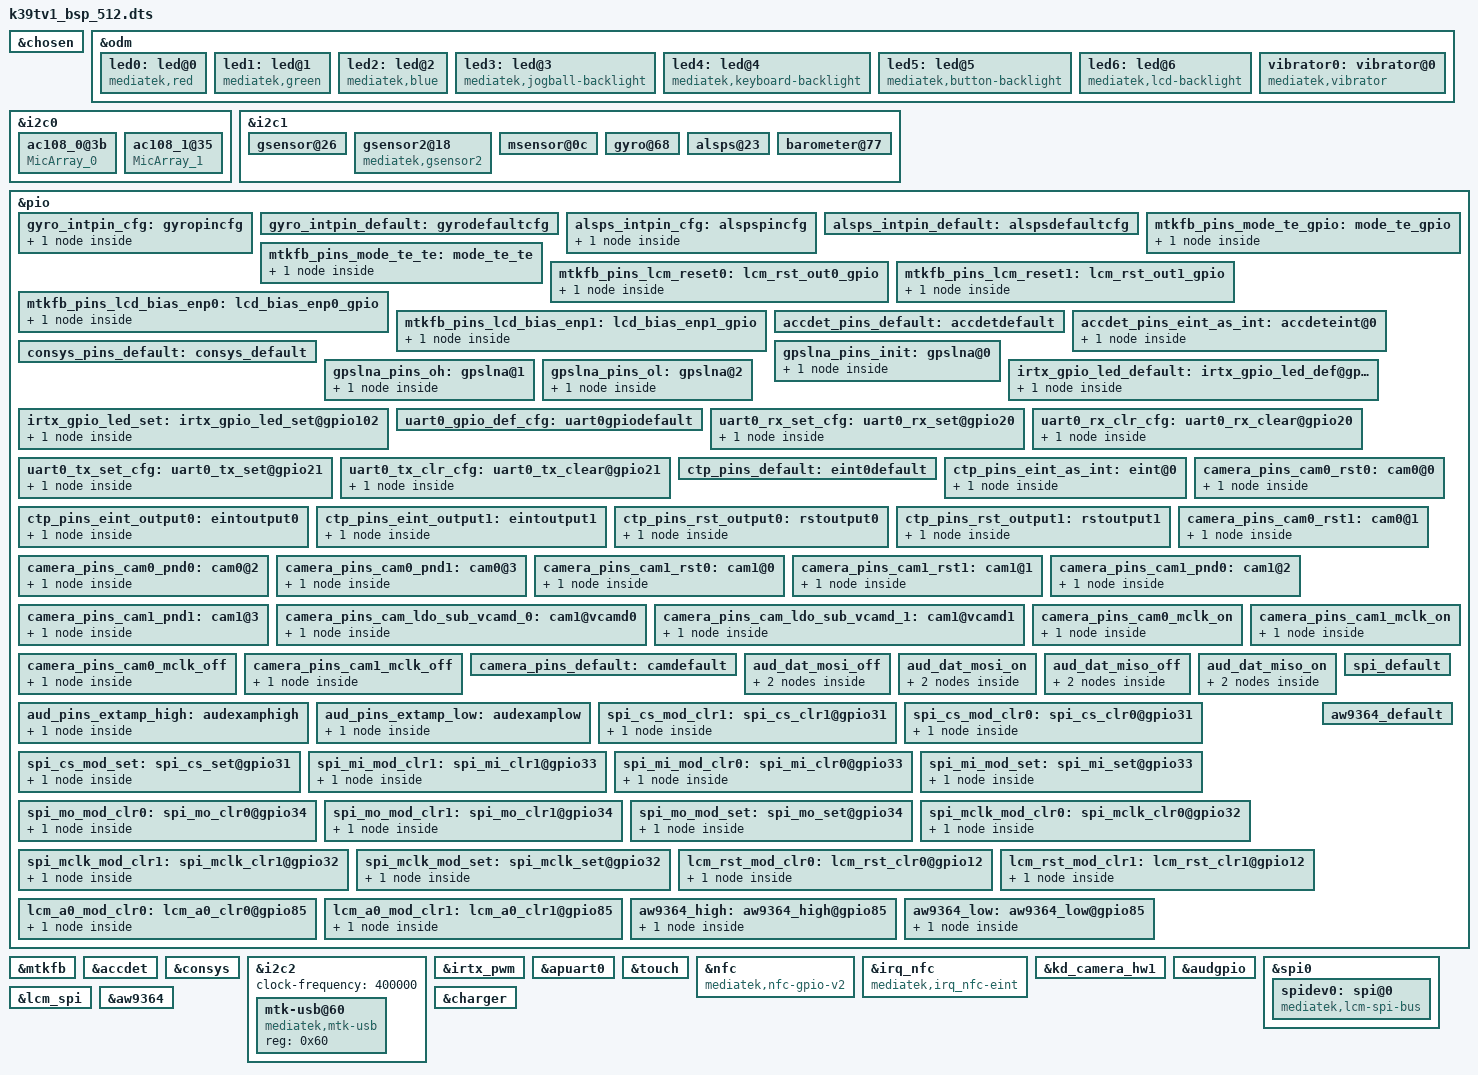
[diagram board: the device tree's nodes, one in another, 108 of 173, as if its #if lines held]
#include <generated/autoconf.h>
/dts-v1/;

#ifdef CONFIG_MTK_DTBO_FEATURE
/plugin/;
#include <dt-bindings/mmc/mt6739-msdc.h>
#include <dt-bindings/pinctrl/mt6739-pinfunc.h>
#else
#include "mt6739.dts"
#endif

/* chosen */
&chosen {
	bootargs = "console=tty0 console=ttyMT0,921600n1 root=/dev/ram initrd=0x44000000,\
0x1000000 loglevel=8 androidboot.selinux=permissive androidboot.hardware=mt6739 initcall_debug=1";
	/* fpga may has no lk, we need to specify display info here */
	/* fb buffer is reserved using this dts by memory node above */

	atag,videolfb-fb_base_l = <0x5e605000>;
	atag,videolfb-fb_base_h = <0>;
	atag,videolfb-islcmfound = <1>;
	atag,videolfb-islcm_inited = <0>;
	atag,videolfb-fps= <6000>;
	atag,videolfb-vramSize= <0x017bb000>;
	atag,videolfb-lcmname= "nt35521_hd_dsi_vdo_truly_nt50358_drv";
};

&odm {
	led0:led@0 {
		compatible = "mediatek,red";
		led_mode = <1>;
		data = <0>;
		pwm_config = <0 0 0 0 0>;
	};
	led1:led@1 {
		compatible = "mediatek,green";
		led_mode = <1>;
		data = <1>;
		pwm_config = <0 0 0 0 0>;
	};
	led2:led@2 {
		compatible = "mediatek,blue";
		led_mode = <1>;
		data = <2>;
		pwm_config = <0 0 0 0 0>;
	};
	led3:led@3 {
		compatible = "mediatek,jogball-backlight";
		led_mode = <0>;
		data = <1>;
		pwm_config = <0 0 0 0 0>;
	};
	led4:led@4 {
		compatible = "mediatek,keyboard-backlight";
		led_mode = <0>;
		data = <1>;
		pwm_config = <0 0 0 0 0>;
	};
	led5:led@5 {
		compatible = "mediatek,button-backlight";
		led_mode = <3>;
		data = <2>;
		pwm_config = <0 0 0 0 0>;
	};
	led6:led@6 {
		compatible = "mediatek,lcd-backlight";
		led_mode = <5>;
		data = <1>;
		pwm_config = <0 2 0 0 0>;
	};
	vibrator0:vibrator@0 {
		compatible = "mediatek,vibrator";
		vib_timer = <25>;
		vib_limit = <9>;
		vib_vol= <9>;
	};
};

/*ac108*/
&i2c0 {
	ac108_0@3b {
		compatible = "MicArray_0";  
		reg = <0x3b>;
		voltage_enable ="vmch";
	};
	ac108_1@35 {
		compatible = "MicArray_1";  
		reg = <0x35>;
		voltage_enable ="vmch";
	};	
};
	
&i2c1 {
/*  start sensor */
	gsensor@26 {
		i2c_num	= <1>;
		direction = <5>;
		power_id = <0xffff>;
		power_vol = <0>;
		firlen = <16>;
		is_batch_supported = <1>;
	};

	gsensor2@18 {
		compatible = "mediatek,gsensor2";  
		reg = <0x18>;
		
		i2c_num	= <1>;
		direction = <5>;
		power_id = <0xffff>;
		power_vol = <0>;
		firlen = <16>;
		is_batch_supported = <1>;
	};
	
	msensor@0c {
		i2c_num = <1>;
		i2c_addr = <0x0d 0 0 0>;
		direction = <8>;
		power_id = <0xffff>;
		power_vol = <0>;
		is_batch_supported = <0>;
	};

	gyro@68 {
		pinctrl-names = "pin_default", "pin_cfg";
		pinctrl-0 = <&gyro_intpin_default>;
		pinctrl-1 = <&gyro_intpin_cfg>;
		i2c_num = <1>;
		i2c_addr = <0x68 0 0 0>;
		direction = <5>;
		power_id = <0xffff>;
		power_vol = <0>;
		firlen = <0>;
		is_batch_supported = <0>;
	};

	alsps@23 {
		pinctrl-names = "pin_default", "pin_cfg";
		pinctrl-0 = <&alsps_intpin_default>;
		pinctrl-1 = <&alsps_intpin_cfg>;
		status = "okay";
		/* customization */
		i2c_num = <1>;
		i2c_addr = <0x23 0 0 0>;
		polling_mode_ps = <0>;
		polling_mode_als = <1>;
		power_id = <0xffff>;
		power_vol = <0>;
		als_level = <0 328 861 1377 3125 7721 7767 12621 23062 28430 33274 47116 57694 57694 65535>;
		als_value = <0 133 304 502 1004 2005 3058 5005 8008 10010 12000 16000 20000 20000 20000 20000>;
		ps_threshold_high = <26>;
		ps_threshold_low = <21>;
		is_batch_supported_ps = <0>;
		is_batch_supported_als = <0>;
	};

	barometer@77 {
		i2c_num = <1>;
		i2c_addr = <0x77 0 0 0>;
		direction = <0>;
		power_id = <0xffff>;
		power_vol = <0>;
		firlen = <32>;
		is_batch_supported = <0>;
	};
/* end sensor */
};

/* sensor gpio standization */
&pio {

	gyro_intpin_cfg: gyropincfg {

	    pins_cmd_dat {
			pins = <PINMUX_GPIO5__FUNC_GPIO5>;
			slew-rate = <0>;
			bias-pull-down = <00>;
		};
	};

	gyro_intpin_default: gyrodefaultcfg {

	};
};

&pio {
	alsps_intpin_cfg: alspspincfg {

		pins_cmd_dat {
			pins = <PINMUX_GPIO102__FUNC_GPIO102>;
			slew-rate = <0>;
			bias-pull-up = <MTK_PUPD_SET_R1R0_01>;
		};
	};

	alsps_intpin_default: alspsdefaultcfg {

	};
};

/* sensor end */

/* DISPSYS GPIO standardization */
&pio {
	mtkfb_pins_mode_te_gpio: mode_te_gpio {
		pins_cmd_dat {
			pins = <PINMUX_GPIO84__FUNC_DSI_TE>;
		};
	};

	mtkfb_pins_mode_te_te: mode_te_te {
		pins_cmd_dat {
			pins = <PINMUX_GPIO84__FUNC_DSI_TE>;
		};
	};

	mtkfb_pins_lcm_reset0: lcm_rst_out0_gpio {
		pins_cmd_dat {
			pins = <PINMUX_GPIO83__FUNC_LCM_RST>;
			slew-rate = <1>;
			output-low;
		};
	};

	mtkfb_pins_lcm_reset1: lcm_rst_out1_gpio {
		pins_cmd_dat {
			pins = <PINMUX_GPIO83__FUNC_LCM_RST>;
			slew-rate = <1>;
			output-high;
		};
	};

	mtkfb_pins_lcd_bias_enp0: lcd_bias_enp0_gpio {
		pins_cmd_dat {
			pins = <PINMUX_GPIO102__FUNC_GPIO102>;
			slew-rate = <1>;
			output-low;
		};
	};
	mtkfb_pins_lcd_bias_enp1: lcd_bias_enp1_gpio {
		pins_cmd_dat {
			pins = <PINMUX_GPIO102__FUNC_GPIO102>;
			slew-rate = <1>;
			output-high;
		};
	};

};

&mtkfb {
	pinctrl-names = "mode_te_gpio", "mode_te_te", "lcm_rst_out0_gpio",
		"lcm_rst_out1_gpio", "lcd_bias_enp0_gpio", "lcd_bias_enp1_gpio";
	pinctrl-0 = <&mtkfb_pins_mode_te_gpio>;
	pinctrl-1 = <&mtkfb_pins_mode_te_te>;
	pinctrl-2 = <&mtkfb_pins_lcm_reset0>;
	pinctrl-3 = <&mtkfb_pins_lcm_reset1>;
	pinctrl-4 = <&mtkfb_pins_lcd_bias_enp0>;
	pinctrl-5 = <&mtkfb_pins_lcd_bias_enp1>;
	status = "okay";
};
/* DISPSYS GPIO standardization end */


/* accdet start */
&accdet {
	/* accdet micbias voltage: 0x07,2.7v;0x05,2.5v;0x02,1.9v */
	accdet-mic-vol = <6>;
	headset-mode-setting = <0x500 0x500 1 0x1f0 0x800 0x800 0x20 0x44>;
	accdet-plugout-debounce = <1>;
	/*1:ACC mode, 2:low cost without in bias, 6:low cost with in bias*/
	accdet-mic-mode = <2>;
	/* eint_level_trigger: 8,LEVEL_LOW(default);4,LEVEL_HIGH;others,LEVEL_LOW */
	headset-eint-level-pol = <8>;
	/*0--MD_MAX--UP_MAX--DW_MAX*/
	headset-three-key-threshold = <0 80 220 400>;
	headset-three-key-threshold-CDD = <0 121 192 600>;
	/*0--MD_MAX--VOICE_MAX--UP_MAX--DW_MAX*/
	headset-four-key-threshold = <0 58 121 192 400>;
	/* ACCDET GPIO standardization ACC mode no use */
	pinctrl-names = "default", "state_eint_as_int";
	pinctrl-0 = <&accdet_pins_default>;
	pinctrl-1 = <&accdet_pins_eint_as_int>;
	status = "okay";
};
&pio {
	accdet_pins_default: accdetdefault {
	};
	accdet_pins_eint_as_int: accdeteint@0 {
		pins_cmd_dat {
			pins = <PINMUX_GPIO13__FUNC_GPIO13>;
			slew-rate = <0>;
			bias-disable;
		};
	};
};
/* accdet end */
/* CONSYS GPIO standardization */
&pio {
	consys_pins_default: consys_default {
	};
	gpslna_pins_init: gpslna@0 {
		pins_cmd_dat {
			pins = <PINMUX_GPIO91__FUNC_GPIO91>;
			slew-rate = <0>;
			bias-disable;
			output-low;
		};
	};
	gpslna_pins_oh: gpslna@1 {
		pins_cmd_dat {
			pins = <PINMUX_GPIO91__FUNC_GPIO91>;
			slew-rate = <1>;
			output-high;
		};
	};
	gpslna_pins_ol: gpslna@2 {
		pins_cmd_dat {
			pins = <PINMUX_GPIO91__FUNC_GPIO91>;
			slew-rate = <1>;
			output-low;
		};
	};
};
&consys {
	pinctrl-names = "default", "gps_lna_state_init", "gps_lna_state_oh", "gps_lna_state_ol";
	pinctrl-0 = <&consys_pins_default>;
	pinctrl-1 = <&gpslna_pins_init>;
	pinctrl-2 = <&gpslna_pins_oh>;
	pinctrl-3 = <&gpslna_pins_ol>;
	status = "okay";
};
&i2c2 {
	#address-cells = <1>;
	#size-cells = <0>;
	clock-frequency = <400000>;

	mtk-usb@60 {
		compatible = "mediatek,mtk-usb";
		reg = <0x60>;
		status = "okay";
	};
};

/* IRTX GPIO Start */
&irtx_pwm {
	pinctrl-names = "irtx_gpio_led_default", "irtx_gpio_led_set";
	pinctrl-0 = <&irtx_gpio_led_default>;
	pinctrl-1 = <&irtx_gpio_led_set>;
	status = "okay";
};
&pio {
	/* IRTX GPIO Settings -Start */
	/* default: GPIO0, output, high */
	irtx_gpio_led_default:irtx_gpio_led_def@gpio102 {
		pins_cmd_dat {
			pins = <PINMUX_GPIO102__FUNC_GPIO102>;
			slew-rate = <1>;
			bias-disable;
			output-low;
			input-schmitt-enable = <0>;
		};
	};

	irtx_gpio_led_set:irtx_gpio_led_set@gpio102 {
		pins_cmd_dat {
			pins = <PINMUX_GPIO102__FUNC_GPIO102>;
			slew-rate = <1>;
			output-high;
		};
	};
}; /* IRTX GPIO Settings -End */

/* UART GPIO */
&apuart0 {
	pinctrl-names = "uart0_gpio_default",
			"uart0_rx_set",
			"uart0_rx_clear",
			"uart0_tx_set",
			"uart0_tx_clear";
	pinctrl-0 = <&uart0_gpio_def_cfg>;
	pinctrl-1 = <&uart0_rx_set_cfg>;
	pinctrl-2 = <&uart0_rx_clr_cfg>;
	pinctrl-3 = <&uart0_tx_set_cfg>;
	pinctrl-4 = <&uart0_tx_clr_cfg>;
	status = "okay";
};

&pio {
	/* UART GPIO Settings - Start */
	/* UART0: rx set, rx clear, tx clear, tx clear*/
	uart0_gpio_def_cfg:uart0gpiodefault {

	};
	uart0_rx_set_cfg:uart0_rx_set@gpio20 {
		pins_cmd_dat {
			pins = <PINMUX_GPIO20__FUNC_UART0RX>;
		};
	};
	uart0_rx_clr_cfg:uart0_rx_clear@gpio20 {
		pins_cmd_dat {
			pins = <PINMUX_GPIO20__FUNC_GPIO20>;
			slew-rate = <1>;
			output-high;
		};
	};
	uart0_tx_set_cfg:uart0_tx_set@gpio21 {
		pins_cmd_dat {
			pins = <PINMUX_GPIO21__FUNC_UART0TX>;
		};
	};
	uart0_tx_clr_cfg:uart0_tx_clear@gpio21 {
		pins_cmd_dat {
			pins = <PINMUX_GPIO21__FUNC_GPIO21>;
			slew-rate = <1>;
			output-high;
		};
	};
};/* UART GPIO end */

/* TOUCH start */
&touch {
	tpd-resolution = <480 854>;
	use-tpd-button = <0>;
	tpd-key-num = <3>;
	tpd-key-local= <139 172 158 0>;
	tpd-key-dim-local = <90 883 100 40 230 883 100 40 370 883 100 40 0 0 0 0>;
	tpd-max-touch-num = <5>;
	tpd-filter-enable = <1>;
	tpd-filter-pixel-density = <71>;
	tpd-filter-custom-prameters = <0 0 0 0 0 0 0 0 0 0 0 0>;
	tpd-filter-custom-speed = <0 0 0>;
	pinctrl-names = "default", "state_eint_as_int", "state_eint_output0", "state_eint_output1",
		"state_rst_output0", "state_rst_output1";
	pinctrl-0 = <&ctp_pins_default>;
	pinctrl-1 = <&ctp_pins_eint_as_int>;
	pinctrl-2 = <&ctp_pins_eint_output0>;
	pinctrl-3 = <&ctp_pins_eint_output1>;
	pinctrl-4 = <&ctp_pins_rst_output0>;
	pinctrl-5 = <&ctp_pins_rst_output1>;
	status = "okay";
};
&pio {
	ctp_pins_default: eint0default {
	};
	ctp_pins_eint_as_int: eint@0 {
		pins_cmd_dat {
			pins = <PINMUX_GPIO4__FUNC_GPIO4>;
			slew-rate = <0>;
			bias-disable;
		};
	};
	ctp_pins_eint_output0: eintoutput0 {
		pins_cmd_dat {
			pins = <PINMUX_GPIO4__FUNC_GPIO4>;
			slew-rate = <1>;
			output-low;
		};
	};
	ctp_pins_eint_output1: eintoutput1 {
		pins_cmd_dat {
			pins = <PINMUX_GPIO4__FUNC_GPIO4>;
			slew-rate = <1>;
			output-high;
		};
	};
	ctp_pins_rst_output0: rstoutput0 {
		pins_cmd_dat {
			pins = <PINMUX_GPIO93__FUNC_GPIO93>;
			slew-rate = <1>;
			output-low;
		};
	};
	ctp_pins_rst_output1: rstoutput1 {
		pins_cmd_dat {
			pins = <PINMUX_GPIO93__FUNC_GPIO93>;
			slew-rate = <1>;
			output-high;
		};
	};
};
/* TOUCH end */

/* NFC start */
&nfc {
	compatible = "mediatek,nfc-gpio-v2";
	gpio-rst = <7>;
	gpio-rst-std = <&pio 7 0x0>;
	gpio-irq = <14>;
	gpio-irq-std = <&pio 14 0x0>;
};

&irq_nfc {
	compatible = "mediatek,irq_nfc-eint";
};
/* NFC end */

/* CAMERA GPIO standardization */
&pio {
	camera_pins_cam0_rst0: cam0@0 {
		pins_cmd_dat {
			pins = <PINMUX_GPIO16__FUNC_GPIO16>;
			slew-rate = <1>; /*direction 0:in, 1:out*/
			output-low;/*direction out used only. output_low or high*/
		};
	};
	camera_pins_cam0_rst1: cam0@1 {
		pins_cmd_dat {
			pins = <PINMUX_GPIO16__FUNC_GPIO16>;
			slew-rate = <1>;
			output-high;
		};
	};
	camera_pins_cam0_pnd0: cam0@2 {
		pins_cmd_dat {
			pins = <PINMUX_GPIO124__FUNC_GPIO124>;
			slew-rate = <1>;
			output-low;
		};
	};
	camera_pins_cam0_pnd1: cam0@3 {
		pins_cmd_dat {
			pins = <PINMUX_GPIO124__FUNC_GPIO124>;
			slew-rate = <1>;
			output-high;
		};
	};
	camera_pins_cam1_rst0: cam1@0 {
		pins_cmd_dat {
			pins = <PINMUX_GPIO19__FUNC_GPIO19>;
			slew-rate = <1>; /*direction 0:in, 1:out*/
			output-low;/*direction out used only. output_low or high*/
		};
	};
	camera_pins_cam1_rst1: cam1@1 {
		pins_cmd_dat {
			pins = <PINMUX_GPIO19__FUNC_GPIO19>;
			slew-rate = <1>;
			output-high;
		};
	};
	camera_pins_cam1_pnd0: cam1@2 {
		pins_cmd_dat {
			pins = <PINMUX_GPIO17__FUNC_GPIO17>;
			slew-rate = <1>;
			output-low;
		};
	};
	camera_pins_cam1_pnd1: cam1@3 {
		pins_cmd_dat {
			pins = <PINMUX_GPIO17__FUNC_GPIO17>;
			slew-rate = <1>;
			output-high;
		};
	};
	camera_pins_cam_ldo_sub_vcamd_0: cam1@vcamd0 {
		pins_cmd_dat {
			pins = <PINMUX_GPIO102__FUNC_GPIO102>;
			slew-rate = <1>;
			output-low;
		};
	};
	camera_pins_cam_ldo_sub_vcamd_1: cam1@vcamd1 {
		pins_cmd_dat {
			pins = <PINMUX_GPIO102__FUNC_GPIO102>;
			slew-rate = <1>;
			output-high;
		};
	};
	camera_pins_cam0_mclk_on: camera_pins_cam0_mclk_on {
		pins_cmd_dat {
			pins = <PINMUX_GPIO126__FUNC_CMMCLK0>;
		};
	};
	camera_pins_cam0_mclk_off: camera_pins_cam0_mclk_off {
		pins_cmd_dat {
			pins = <PINMUX_GPIO126__FUNC_GPIO126>;
		};
	};
	camera_pins_cam1_mclk_on: camera_pins_cam1_mclk_on {
		pins_cmd_dat {
			pins = <PINMUX_GPIO127__FUNC_CMMCLK1>;
		};
	};
	camera_pins_cam1_mclk_off: camera_pins_cam1_mclk_off {
		pins_cmd_dat {
			pins = <PINMUX_GPIO127__FUNC_GPIO127>;
		};
	};
	camera_pins_default: camdefault {
	};
};

&kd_camera_hw1 {
	pinctrl-names = "default",
			"cam0_rst0", "cam0_rst1", "cam0_pnd0", "cam0_pnd1",
			"cam1_rst0", "cam1_rst1", "cam1_pnd0", "cam1_pnd1",
			"cam_ldo_sub_vcamd_0", "cam_ldo_sub_vcamd_1",
			"cam0_mclk_on", "cam0_mclk_off",
			"cam1_mclk_on", "cam1_mclk_off";

	pinctrl-0 = <&camera_pins_default>;
	pinctrl-1 = <&camera_pins_cam0_rst0>;
	pinctrl-2 = <&camera_pins_cam0_rst1>;
	pinctrl-3 = <&camera_pins_cam0_pnd0>;
	pinctrl-4 = <&camera_pins_cam0_pnd1>;
	pinctrl-5 = <&camera_pins_cam1_rst0>;
	pinctrl-6 = <&camera_pins_cam1_rst1>;
	pinctrl-7 = <&camera_pins_cam1_pnd0>;
	pinctrl-8 = <&camera_pins_cam1_pnd1>;
	pinctrl-9 = <&camera_pins_cam_ldo_sub_vcamd_0>;
	pinctrl-10 = <&camera_pins_cam_ldo_sub_vcamd_1>;
	pinctrl-11 = <&camera_pins_cam0_mclk_on>;
	pinctrl-12 = <&camera_pins_cam0_mclk_off>;
	pinctrl-13 = <&camera_pins_cam1_mclk_on>;
	pinctrl-14 = <&camera_pins_cam1_mclk_off>;
	status = "okay";

};
/* CAMERA GPIO end */

/* AUDIO GPIO standardization */
&audgpio {
	pinctrl-names = "aud_dat_mosi_off",
			"aud_dat_mosi_on",
			"aud_dat_miso_off",
			"aud_dat_miso_on",
			"extamp-pullhigh",
			"extamp-pulllow";
	pinctrl-0 = <&aud_dat_mosi_off>;
	pinctrl-1 = <&aud_dat_mosi_on>;
	pinctrl-2 = <&aud_dat_miso_off>;
	pinctrl-3 = <&aud_dat_miso_on>;
	pinctrl-4 = <&aud_pins_extamp_high>;
	pinctrl-5 = <&aud_pins_extamp_low>;
	status = "okay";
};

&pio {
	aud_dat_mosi_off: aud_dat_mosi_off {
		pins_cmd1_dat {
			pins = <PINMUX_GPIO63__FUNC_GPIO63>;
			input-enable;
			slew-rate = <0>;
			bias-disable;
		};
		pins_cmd2_dat {
			pins = <PINMUX_GPIO64__FUNC_GPIO64>;
			input-enable;
			slew-rate = <0>;
			bias-disable;
		};
	};

	aud_dat_mosi_on: aud_dat_mosi_on {
		pins_cmd1_dat {
			pins = <PINMUX_GPIO63__FUNC_AUD_DAT_MOSI0>;
		};
		pins_cmd2_dat {
			pins = <PINMUX_GPIO64__FUNC_AUD_DAT_MOSI1>;
		};
	};

	aud_dat_miso_off: aud_dat_miso_off {
		pins_cmd1_dat {
			pins = <PINMUX_GPIO67__FUNC_GPIO67>;
			input-enable;
			slew-rate = <0>;
			bias-disable;
		};
		pins_cmd2_dat {
			pins = <PINMUX_GPIO68__FUNC_GPIO68>;
			input-enable;
			slew-rate = <0>;
			bias-disable;
		};
	};

	aud_dat_miso_on: aud_dat_miso_on {
		pins_cmd1_dat {
			pins = <PINMUX_GPIO67__FUNC_AUD_DAT_MISO0>;
		};
		pins_cmd2_dat {
			pins = <PINMUX_GPIO68__FUNC_AUD_DAT_MISO1>;
		};
	};
	aud_pins_extamp_high: audexamphigh {
		pins_cmd_dat {
			pins = <PINMUX_GPIO1__FUNC_GPIO1>;
			slew-rate = <1>;
			output-high;
		};
	};

	aud_pins_extamp_low: audexamplow {
		pins_cmd_dat {
			pins = <PINMUX_GPIO1__FUNC_GPIO1>;
			slew-rate = <1>;
			output-low;
		};
	};

};
/* AUDIO end */

/* lcm_spi begin*/
&pio {
	spi_default: spi_default {
	};

	spi_cs_mod_clr1: spi_cs_clr1@gpio31 {
		pins_cmd_dat {
			pins = <PINMUX_GPIO31__FUNC_GPIO31>;
			slew-rate = <1>;
			output-high;
		};
	};
	spi_cs_mod_clr0: spi_cs_clr0@gpio31 {
		pins_cmd_dat {
			pins = <PINMUX_GPIO31__FUNC_GPIO31>;
			slew-rate = <1>;
			output-low;
		};
	};
	spi_cs_mod_set: spi_cs_set@gpio31 {
		pins_cmd_dat {
			pins = <PINMUX_GPIO31__FUNC_SPI0_A_CSB>;
			input-enable;
		};
	};	
	spi_mi_mod_clr1: spi_mi_clr1@gpio33 {
		pins_cmd_dat {
			pins = <PINMUX_GPIO33__FUNC_GPIO33>;
			slew-rate = <1>;
			output-high;
		};
	};
	spi_mi_mod_clr0: spi_mi_clr0@gpio33 {
		pins_cmd_dat {
			pins = <PINMUX_GPIO33__FUNC_GPIO33>;
			slew-rate = <1>;
			output-low;
		};
	};
	spi_mi_mod_set: spi_mi_set@gpio33 {
		pins_cmd_dat {
			pins = <PINMUX_GPIO33__FUNC_SPI0_A_MI>;
			input-enable;
		};
	};	
	spi_mo_mod_clr0: spi_mo_clr0@gpio34 {
		pins_cmd_dat {
			pins = <PINMUX_GPIO34__FUNC_GPIO34>;
			slew-rate = <1>;
			output-low;
		};
	};
	spi_mo_mod_clr1: spi_mo_clr1@gpio34 {
		pins_cmd_dat {
			pins = <PINMUX_GPIO34__FUNC_GPIO34>;
			slew-rate = <1>;
			output-high;
		};
	};
	spi_mo_mod_set: spi_mo_set@gpio34 {
		pins_cmd_dat {
			pins = <PINMUX_GPIO34__FUNC_SPI0_A_MO>;
			input-enable;
		};
	};	
	spi_mclk_mod_clr0: spi_mclk_clr0@gpio32 {
		pins_cmd_dat {
			pins = <PINMUX_GPIO32__FUNC_GPIO32>;
			slew-rate = <1>;
			output-low;
		};
	};
	spi_mclk_mod_clr1: spi_mclk_clr1@gpio32 {
		pins_cmd_dat {
			pins = <PINMUX_GPIO32__FUNC_GPIO32>;
			slew-rate = <1>;
			output-high;
		};
	};
	spi_mclk_mod_set: spi_mclk_set@gpio32 {
		pins_cmd_dat {
			pins = <PINMUX_GPIO32__FUNC_SPI0_A_CLK>;
			input-enable;
		};
	};	
	lcm_rst_mod_clr0: lcm_rst_clr0@gpio12 {
		pins_cmd_dat {
			pins = <PINMUX_GPIO12__FUNC_GPIO12>;
			slew-rate = <1>;
			output-low;
		};
	};
	lcm_rst_mod_clr1: lcm_rst_clr1@gpio12 {
		pins_cmd_dat {
			pins = <PINMUX_GPIO12__FUNC_GPIO12>;
			slew-rate = <1>;
			output-high;
		};
	};
	lcm_a0_mod_clr0: lcm_a0_clr0@gpio85 {
		pins_cmd_dat {
			pins = <PINMUX_GPIO85__FUNC_GPIO85>;
			slew-rate = <1>;
			output-low;
		};
	};
	lcm_a0_mod_clr1: lcm_a0_clr1@gpio85 {
		pins_cmd_dat {
			pins = <PINMUX_GPIO85__FUNC_GPIO85>;
			slew-rate = <1>;
			output-high;
		};
	};	
	
};


&spi0 {
	status = "okay";
	#address-cells = <1> ;
	#size-cells = <0> ;
	spidev0: spi@0 {
		compatible = "mediatek,lcm-spi-bus";
		reg = <0>;
		spi-max-frequency = <16000000>;
	};
};


&lcm_spi {
	pinctrl-names = "spi_default", "spi_cs_clr1", "spi_cs_clr0", "spi_cs_set","spi_mi_clr1","spi_mi_clr0","spi_mi_set",
					"spi_mo_clr0", "spi_mo_clr1", "spi_mo_set","spi_mclk_clr0","spi_mclk_clr1","spi_mclk_set",
					"lcm_rst_clr0","lcm_rst_clr1","lcm_a0_clr0","lcm_a0_clr1";
	pinctrl-0 = <&spi_default>;
	pinctrl-1 = <&spi_cs_mod_clr1>;   // default
	pinctrl-2 = <&spi_cs_mod_clr0>;
	pinctrl-3 = <&spi_cs_mod_set>;
	pinctrl-4 = <&spi_mi_mod_clr1>;    // default
	pinctrl-5 = <&spi_mi_mod_clr0>;
	pinctrl-6 = <&spi_mi_mod_set>;
	pinctrl-7 = <&spi_mo_mod_clr0>;   // default
	pinctrl-8 = <&spi_mo_mod_clr1>;
	pinctrl-9 = <&spi_mo_mod_set>;
	pinctrl-10 = <&spi_mclk_mod_clr0>;  // default
	pinctrl-11 = <&spi_mclk_mod_clr1>;
	pinctrl-12 = <&spi_mclk_mod_set>;	
	pinctrl-13 = <&lcm_rst_mod_clr0>;
	pinctrl-14 = <&lcm_rst_mod_clr1>;
	pinctrl-15 = <&lcm_a0_mod_clr0>;
	pinctrl-16 = <&lcm_a0_mod_clr1>;	
	status = "okay";
};
/* lcm_spi end*/

/*  aw9364 begin*/
&pio {
	aw9364_default: aw9364_default {
	};
	aw9364_high: aw9364_high@gpio85{
		pins_cmd_dat {
			pins = <PINMUX_GPIO85__FUNC_GPIO85>;
			slew-rate = <1>;
			output-high;
		};
	};
	aw9364_low: aw9364_low@gpio85{
		pins_cmd_dat {
			pins = <PINMUX_GPIO85__FUNC_GPIO85>;
			slew-rate = <1>;
			output-low;
		};
	};		
};

&aw9364 {
	pinctrl-names = "aw9364_default", "aw9364_high", "aw9364_low";
	pinctrl-0 = <&aw9364_default>;
	pinctrl-1 = <&aw9364_high>;
	pinctrl-2 = <&aw9364_low>;
	status = "okay";
};
/* aw9364 end*/

/*LinearCharging begin*/
&charger {
      algorithm_name = "LinearCharging";
      ac_charger_current = <1000000>;
      charging_host_charger_current = <1000000>;
};
/*LinearCharging end*/

#include <k39tv1_bsp_512/cust.dtsi>
/*End of this file, DO NOT ADD ANYTHING HERE*/
